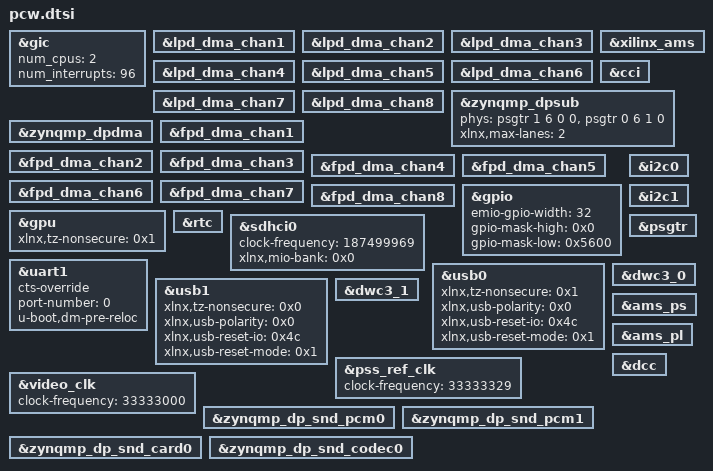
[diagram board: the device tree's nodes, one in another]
/*
 * CAUTION: This file is automatically generated by Xilinx.
 * Version: XSCT 
 * Today is: Thu Nov 13 13:33:39 2025
 */


&gic {
	num_cpus = <2>;
	num_interrupts = <96>;
};
&lpd_dma_chan1 {
	status = "okay";
};
&lpd_dma_chan2 {
	status = "okay";
};
&lpd_dma_chan3 {
	status = "okay";
};
&lpd_dma_chan4 {
	status = "okay";
};
&lpd_dma_chan5 {
	status = "okay";
};
&lpd_dma_chan6 {
	status = "okay";
};
&lpd_dma_chan7 {
	status = "okay";
};
&lpd_dma_chan8 {
	status = "okay";
};
&xilinx_ams {
	status = "okay";
};
&cci {
	status = "okay";
};
&zynqmp_dpsub {
	phy-names = "dp-phy0","dp-phy1";
	phys = <&psgtr 1 6 0 0>, <&psgtr 0 6 1 0>;
	status = "okay";
	xlnx,max-lanes = <2>;
};
&zynqmp_dpdma {
	status = "okay";
};
&fpd_dma_chan1 {
	status = "okay";
};
&fpd_dma_chan2 {
	status = "okay";
};
&fpd_dma_chan3 {
	status = "okay";
};
&fpd_dma_chan4 {
	status = "okay";
};
&fpd_dma_chan5 {
	status = "okay";
};
&fpd_dma_chan6 {
	status = "okay";
};
&fpd_dma_chan7 {
	status = "okay";
};
&fpd_dma_chan8 {
	status = "okay";
};
&gpio {
	emio-gpio-width = <32>;
	gpio-mask-high = <0x0>;
	gpio-mask-low = <0x5600>;
	status = "okay";
};
&gpu {
	status = "okay";
	xlnx,tz-nonsecure = <0x1>;
};
&i2c0 {
	status = "okay";
};
&i2c1 {
	status = "okay";
};
&rtc {
	status = "okay";
};
&sdhci0 {
	clock-frequency = <187499969>;
	status = "okay";
	xlnx,mio-bank = <0x0>;
};
&psgtr {
	status = "okay";
};
&uart1 {
	cts-override ;
	device_type = "serial";
	port-number = <0>;
	status = "okay";
	u-boot,dm-pre-reloc ;
};
&usb0 {
	status = "okay";
	xlnx,tz-nonsecure = <0x1>;
	xlnx,usb-polarity = <0x0>;
	xlnx,usb-reset-io = <0x4c>;
	xlnx,usb-reset-mode = <0x1>;
};
&usb1 {
	status = "okay";
	xlnx,tz-nonsecure = <0x0>;
	xlnx,usb-polarity = <0x0>;
	xlnx,usb-reset-io = <0x4c>;
	xlnx,usb-reset-mode = <0x1>;
};
&dwc3_0 {
	status = "okay";
};
&dwc3_1 {
	status = "okay";
};
&pss_ref_clk {
	clock-frequency = <33333329>;
};
&video_clk {
	clock-frequency = <33333000>;
};
&ams_ps {
	status = "okay";
};
&ams_pl {
	status = "okay";
};
&dcc {
	status = "okay";
};
&zynqmp_dp_snd_pcm0 {
	status = "okay";
};
&zynqmp_dp_snd_pcm1 {
	status = "okay";
};
&zynqmp_dp_snd_card0 {
	status = "okay";
};
&zynqmp_dp_snd_codec0 {
	status = "okay";
};
